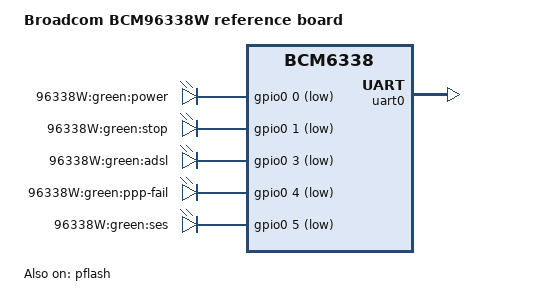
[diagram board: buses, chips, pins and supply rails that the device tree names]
/dts-v1/;

#include "bcm6338.dtsi"

#include <dt-bindings/input/input.h>

/ {
	model = "Broadcom BCM96338W reference board";
	compatible = "brcm,bcm96338w", "brcm,bcm6338";

	chosen {
		bootargs = "rootfstype=squashfs,jffs2 noinitrd console=ttyS0,115200";
		stdout-path = "serial0:115200n8";
	};

	gpio-leds {
		compatible = "gpio-leds";

		power_green {
			label = "96338W:green:power";
			gpios = <&gpio0 0 1>;
			default-state = "on";
		};
		stop_green {
			label = "96338W:green:stop";
			gpios = <&gpio0 1 1>;
		};
		dsl_green {
			label = "96338W:green:adsl";
			gpios = <&gpio0 3 1>;
		};
		ppp_fail_green {
			label = "96338W:green:ppp-fail";
			gpios = <&gpio0 4 1>;
		};
		ses_green {
			label = "96338W:green:ses";
			gpios = <&gpio0 5 1>;
		};
	};
};

&pflash {
	status = "ok";

	linux,part-probe = "bcm63xxpart";

	partitions {
		compatible = "brcm,bcm963xx-cfe-nor-partitions";
	};
};

&uart0 {
	status = "ok";
};
